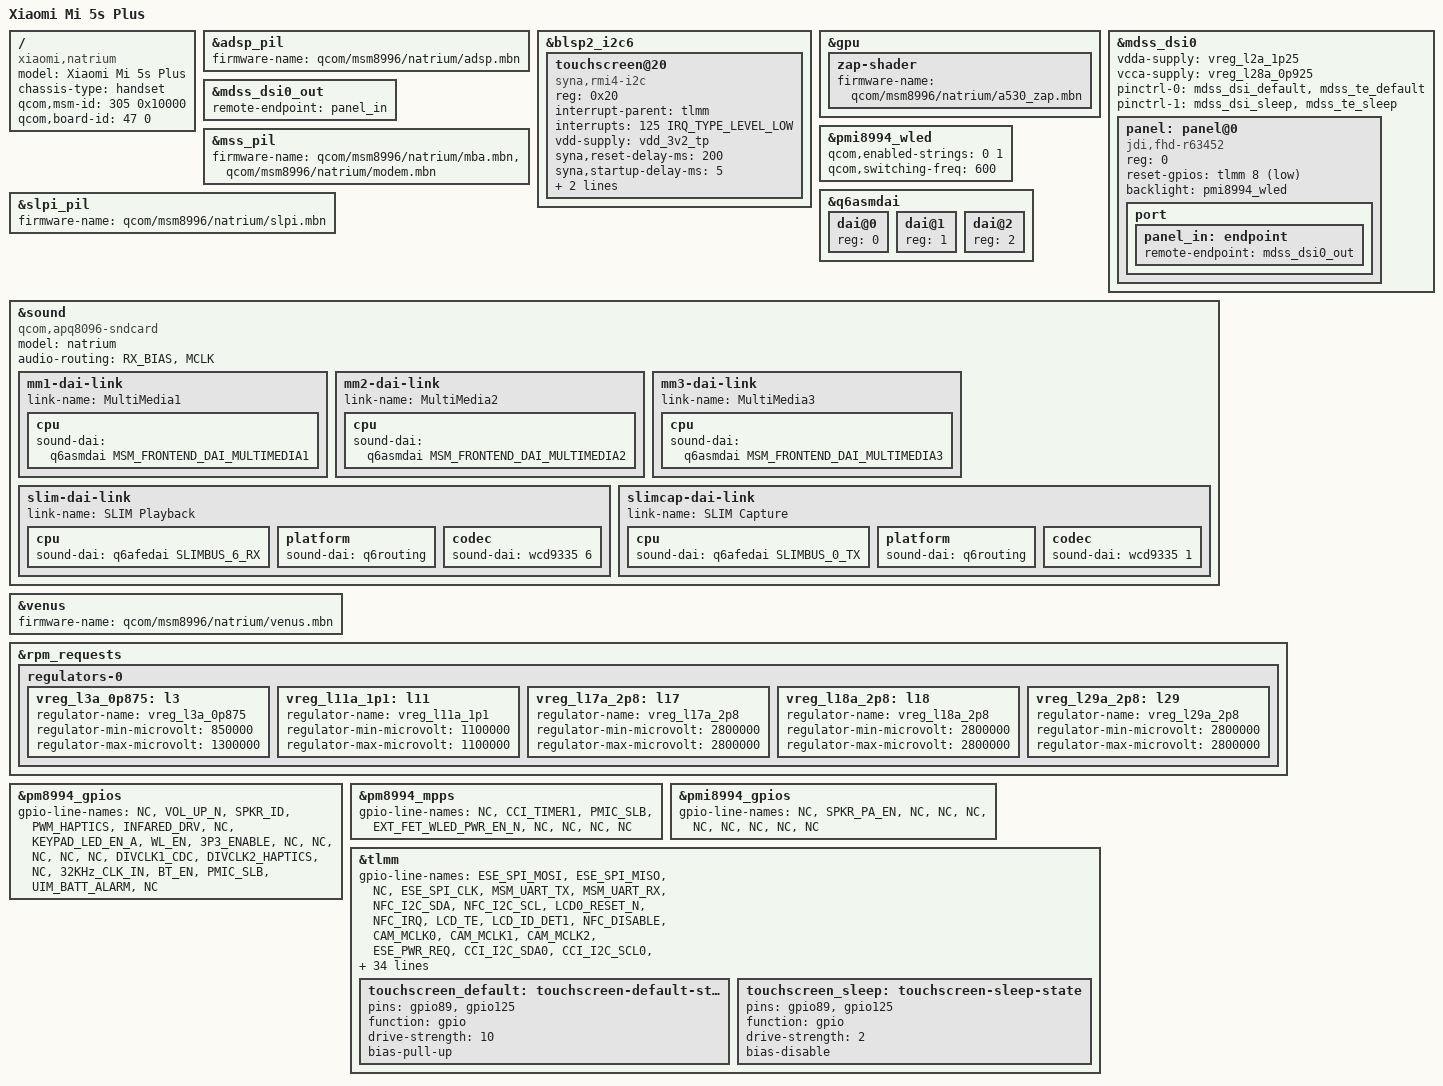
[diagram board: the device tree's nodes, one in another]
/dts-v1/;
#include "msm8996pro.dtsi"
#include "msm8996-xiaomi-common.dtsi"
#include "pmi8996.dtsi"
#include <dt-bindings/sound/qcom,q6afe.h>
#include <dt-bindings/sound/qcom,q6asm.h>
/ {
	model = "Xiaomi Mi 5s Plus";
	compatible = "xiaomi,natrium", "qcom,msm8996pro", "qcom,msm8996";
	chassis-type = "handset";
	qcom,msm-id = <305 0x10000>;
	qcom,board-id = <47 0>;
};
&adsp_pil {
	firmware-name = "qcom/msm8996/natrium/adsp.mbn";
};
&blsp2_i2c6 {
	touchscreen@20 {
		compatible = "syna,rmi4-i2c";
		reg = <0x20>;
		interrupt-parent = <&tlmm>;
		interrupts = <125 IRQ_TYPE_LEVEL_LOW>;
		vdd-supply = <&vdd_3v2_tp>;
		syna,reset-delay-ms = <200>;
		syna,startup-delay-ms = <5>;
		pinctrl-names = "default", "sleep";
		pinctrl-0 = <&touchscreen_default>;
		pinctrl-1 = <&touchscreen_sleep>;
	};
};
&gpu {
	zap-shader {
		firmware-name = "qcom/msm8996/natrium/a530_zap.mbn";
	};
};
&mdss_dsi0 {
	status = "okay";
	vdda-supply = <&vreg_l2a_1p25>;
	vcca-supply = <&vreg_l28a_0p925>;
	pinctrl-names = "default", "sleep";
	pinctrl-0 = <&mdss_dsi_default &mdss_te_default>;
	pinctrl-1 = <&mdss_dsi_sleep &mdss_te_sleep>;
	panel: panel@0 {
		compatible = "jdi,fhd-r63452";
		reg = <0>;
		reset-gpios = <&tlmm 8 GPIO_ACTIVE_LOW>;
		backlight = <&pmi8994_wled>;
		port {
			panel_in: endpoint {
				remote-endpoint = <&mdss_dsi0_out>;
			};
		};
	};
};
&mdss_dsi0_out {
	remote-endpoint = <&panel_in>;
};
&mss_pil {
	firmware-name = "qcom/msm8996/natrium/mba.mbn",
			"qcom/msm8996/natrium/modem.mbn";
};
&pmi8994_wled {
	status = "okay";
	qcom,enabled-strings = <0 1>;
	qcom,switching-freq = <600>;
};
&q6asmdai {
	dai@0 {
		reg = <0>;
	};
	dai@1 {
		reg = <1>;
	};
	dai@2 {
		reg = <2>;
	};
};
&slpi_pil {
	firmware-name = "qcom/msm8996/natrium/slpi.mbn";
};
&sound {
	compatible = "qcom,apq8096-sndcard";
	model = "natrium";
	audio-routing = "RX_BIAS", "MCLK";
	mm1-dai-link {
		link-name = "MultiMedia1";
		cpu {
			sound-dai = <&q6asmdai MSM_FRONTEND_DAI_MULTIMEDIA1>;
		};
	};
	mm2-dai-link {
		link-name = "MultiMedia2";
		cpu {
			sound-dai = <&q6asmdai MSM_FRONTEND_DAI_MULTIMEDIA2>;
		};
	};
	mm3-dai-link {
		link-name = "MultiMedia3";
		cpu {
			sound-dai = <&q6asmdai MSM_FRONTEND_DAI_MULTIMEDIA3>;
		};
	};
	slim-dai-link {
		link-name = "SLIM Playback";
		cpu {
			sound-dai = <&q6afedai SLIMBUS_6_RX>;
		};
		platform {
			sound-dai = <&q6routing>;
		};
		codec {
			sound-dai = <&wcd9335 6>;
		};
	};
	slimcap-dai-link {
		link-name = "SLIM Capture";
		cpu {
			sound-dai = <&q6afedai SLIMBUS_0_TX>;
		};
		platform {
			sound-dai = <&q6routing>;
		};
		codec {
			sound-dai = <&wcd9335 1>;
		};
	};
};
&venus {
	firmware-name = "qcom/msm8996/natrium/venus.mbn";
};
&rpm_requests {
	regulators-0 {
		vreg_l3a_0p875: l3 {
			regulator-name = "vreg_l3a_0p875";
			regulator-min-microvolt = <850000>;
			regulator-max-microvolt = <1300000>;
		};
		vreg_l11a_1p1: l11 {
			regulator-name = "vreg_l11a_1p1";
			regulator-min-microvolt = <1100000>;
			regulator-max-microvolt = <1100000>;
		};
		vreg_l17a_2p8: l17 {
			regulator-name = "vreg_l17a_2p8";
			regulator-min-microvolt = <2800000>;
			regulator-max-microvolt = <2800000>;
		};
		vreg_l18a_2p8: l18 {
			regulator-name = "vreg_l18a_2p8";
			regulator-min-microvolt = <2800000>;
			regulator-max-microvolt = <2800000>;
		};
		vreg_l29a_2p8: l29 {
			regulator-name = "vreg_l29a_2p8";
			regulator-min-microvolt = <2800000>;
			regulator-max-microvolt = <2800000>;
		};
	};
};
&pm8994_gpios {
	gpio-line-names =
		"NC",			 
		"VOL_UP_N",		 
		"SPKR_ID",		 
		"PWM_HAPTICS",		 
		"INFARED_DRV",		 
		"NC",			 
		"KEYPAD_LED_EN_A",	 
		"WL_EN",		 
		"3P3_ENABLE",		 
		"NC",			 
		"NC",			 
		"NC",			 
		"NC",			 
		"NC",			 
		"DIVCLK1_CDC",		 
		"DIVCLK2_HAPTICS",	 
		"NC",			 
		"32KHz_CLK_IN",		 
		"BT_EN",		 
		"PMIC_SLB",		 
		"UIM_BATT_ALARM",	 
		"NC";			 
};
&pm8994_mpps {
	gpio-line-names =
		"NC",			 
		"CCI_TIMER1",		 
		"PMIC_SLB",		 
		"EXT_FET_WLED_PWR_EN_N", 
		"NC",			 
		"NC",			 
		"NC",			 
		"NC";			 
};
&pmi8994_gpios {
	gpio-line-names =
		"NC",			 
		"SPKR_PA_EN",		 
		"NC",			 
		"NC",			 
		"NC",			 
		"NC",			 
		"NC",			 
		"NC",			 
		"NC",			 
		"NC";			 
};
&tlmm {
	gpio-line-names =
		"ESE_SPI_MOSI",		 
		"ESE_SPI_MISO",		 
		"NC",			 
		"ESE_SPI_CLK",		 
		"MSM_UART_TX",		 
		"MSM_UART_RX",		 
		"NFC_I2C_SDA",		 
		"NFC_I2C_SCL",		 
		"LCD0_RESET_N",		 
		"NFC_IRQ",		 
		"LCD_TE",		 
		"LCD_ID_DET1",		 
		"NFC_DISABLE",		 
		"CAM_MCLK0",		 
		"CAM_MCLK1",		 
		"CAM_MCLK2",		 
		"ESE_PWR_REQ",		 
		"CCI_I2C_SDA0",		 
		"CCI_I2C_SCL0",		 
		"CCI_I2C_SDA1",		 
		"CCI_I2C_SCL1",		 
		"NFC_DWL_REQ",		 
		"CCI_TIMER1",		 
		"WEBCAM1_RESET_N",	 
		"ESE_IRQ",		 
		"NC",			 
		"WEBCAM1_STANDBY",	 
		"NC",			 
		"NC",			 
		"NC",			 
		"CAM_VDD_1P2_EN_2",	 
		"CAM_RESET_0",		 
		"CAM_RESET_1",		 
		"NC",			 
		"NC",			 
		"PCI_E0_RST_N",		 
		"PCI_E0_CLKREQ_N",	 
		"PCI_E0_WAKE",		 
		"CHARGER_INT",		 
		"CHARGER_RESET",	 
		"NC",			 
		"QCA_UART_TXD",		 
		"QCA_UART_RXD",		 
		"QCA_UART_CTS",		 
		"QCA_UART_RTS",		 
		"MAWC_UART_TX",		 
		"MAWC_UART_RX",		 
		"NC",			 
		"NC",			 
		"NC",			 
		"FP_SPI_RST",		 
		"TYPEC_I2C_SDA",	 
		"TYPEC_I2C_SCL",	 
		"CODEC_INT2_N",		 
		"CODEC_INT1_N",		 
		"APPS_I2C7_SDA",	 
		"APPS_I2C7_SCL",	 
		"FORCE_USB_BOOT",	 
		"NC",			 
		"NC",			 
		"NC",			 
		"NC",			 
		"ESE_RSTN",		 
		"TYPEC_INT",		 
		"CODEC_RESET_N",	 
		"PCM_CLK",		 
		"PCM_SYNC",		 
		"PCM_DIN",		 
		"PCM_DOUT",		 
		"CDC_44K1_CLK",		 
		"SLIMBUS_CLK",		 
		"SLIMBUS_DATA0",	 
		"SLIMBUS_DATA1",	 
		"LDO_5V_IN_EN",		 
		"TYPEC_EN_N",		 
		"NC",			 
		"NC",			 
		"NC",			 
		"NC",			 
		"NC",			 
		"SENSOR_RESET_N",	 
		"FP_SPI_MOSI",		 
		"FP_SPI_MISO",		 
		"FP_SPI_CS_N",		 
		"FP_SPI_CLK",		 
		"NC",			 
		"CAM_VDD_1P2_EN",	 
		"MSM_TS_I2C_SDA",	 
		"MSM_TS_I2C_SCL",	 
		"TS_RESOUT_N",		 
		"ESE_SPI_CS_N",		 
		"NC",			 
		"CAM2_AVDD_EN",		 
		"CAM2_VCM_EN",		 
		"NC",			 
		"NC",			 
		"NC",			 
		"GRFC_0",		 
		"GRFC_1",		 
		"NC",			 
		"GRFC_3",		 
		"GRFC_4",		 
		"GRFC_5",		 
		"NC",			 
		"GRFC_7",		 
		"UIM2_DATA",		 
		"UIM2_CLK",		 
		"UIM2_RESET",		 
		"UIM2_PRESENT",		 
		"UIM1_DATA",		 
		"UIM1_CLK",		 
		"UIM1_RESET",		 
		"UIM1_PRESENT",		 
		"UIM_BATT_ALARM",	 
		"GRFC_8",		 
		"GRFC_9",		 
		"TX_GTR_THRES",		 
		"ACCEL_INT",		 
		"GYRO_INT",		 
		"COMPASS_INT",		 
		"PROXIMITY_INT_N",	 
		"FP_IRQ",		 
		"P_SENSE",		 
		"HALL_INTR2",		 
		"HALL_INTR1",		 
		"TS_INT_N",		 
		"NC",			 
		"GRFC_11",		 
		"NC",			 
		"EXT_GPS_LNA_EN",	 
		"NC",			 
		"LCD_ID_DET2",		 
		"LCD_TE2",		 
		"GRFC_14",		 
		"GSM_TX2_PHASE_D",	 
		"NC",			 
		"GRFC_15",		 
		"RFFE3_DATA",		 
		"RFFE3_CLK",		 
		"NC",			 
		"NC",			 
		"RFFE5_DATA",		 
		"RFFE5_CLK",		 
		"NC",			 
		"COEX_UART_TX",		 
		"COEX_UART_RX",		 
		"RFFE2_DATA",		 
		"RFFE2_CLK",		 
		"RFFE1_DATA",		 
		"RFFE1_CLK";		 
	touchscreen_default: touchscreen-default-state {
		pins = "gpio89", "gpio125";
		function = "gpio";
		drive-strength = <10>;
		bias-pull-up;
	};
	touchscreen_sleep: touchscreen-sleep-state {
		pins = "gpio89", "gpio125";
		function = "gpio";
		drive-strength = <2>;
		bias-disable;
	};
};
